# STM32L041xx register map
File version: 1.0
Registers are 32-bit, read-write, reset 0x0 unless marked. A register's access mark holds for its fields unless they carry their own. Offsets are from the block's base; [hi:lo] are bit positions; {n}, {i} and the like mark numbered series; 'fields as' and 'values as' point back to an identical list.

## SPI1 — Serial Peripheral Interface
Base 0x40013000
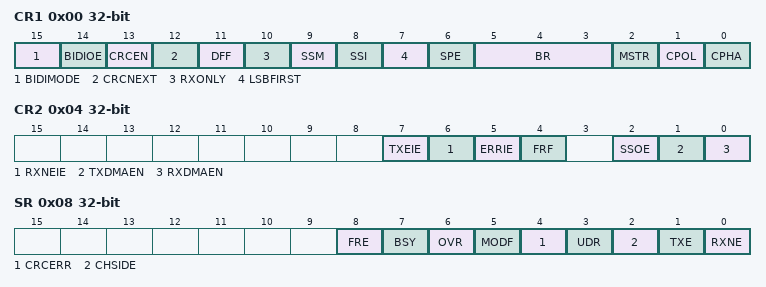
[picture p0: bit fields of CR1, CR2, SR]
0x00 CR1 — SPI Control register 1
  [15] BIDIMODE — Bidirectional data mode enable
  [14] BIDIOE — Output enable in bidirectional mode
  [13] CRCEN — Hardware CRC calculation enable
  [12] CRCNEXT — Transmit CRC next
  [11] DFF — Data Frame Format
    0=DATAWIDTH_8BIT (Data length for SPI transfer: 8 bits); 1=DATAWIDTH_16BIT (Data length for SPI transfer: 16 bits)
  [10] RXONLY — Receive only
  [9] SSM — Software slave management
  [8] SSI — Internal slave select
  [7] LSBFIRST — Frame Format
    1=LSB_FIRST (Data is transmitted/received with the LSB first); 0=MSB_FIRST (Data is transmitted/received with the MSB first)
  [6] SPE — SPI Enable
  [5:3] BR — BR[2:0] bits (Baud Rate Control)
    0=DIV2 (BaudRate control equal to fPCLK/2); 1=DIV4 (BaudRate control equal to fPCLK/4); 2=DIV8 (BaudRate control equal to fPCLK/8); 3=DIV16 (BaudRate control equal to fPCLK/16); 4=DIV32 (BaudRate control equal to fPCLK/32); 5=DIV64 (BaudRate control equal to fPCLK/64); 6=DIV128 (BaudRate control equal to fPCLK/128); 7=DIV256 (BaudRate control equal to fPCLK/256)
  [2] MSTR — Master Selection
  [1] CPOL — Clock Polarity
    0=LOW (Clock to 0 when idle); 1=HIGH (Clock to 1 when idle)
  [0] CPHA — Clock Phase
    0=PHASE_1EDGE (First clock transition is the first data capture edge); 1=PHASE_2EDGE (Second clock transition is the first data capture edge)
0x04 CR2 — SPI Control register 2
  [7] TXEIE — Tx buffer Empty Interrupt Enable
  [6] RXNEIE — RX buffer Not Empty Interrupt Enable
  [5] ERRIE — Error Interrupt Enable
  [4] FRF — Frame Format Enable
    0=MOTOROLA (Motorola mode. Used as default value); 1=TI (TI mode)
  [2] SSOE — SS Output Enable
  [1] TXDMAEN — Tx Buffer DMA Enable
  [0] RXDMAEN — Rx Buffer DMA Enable
0x08 SR — SPI Status register
  [8] FRE — TI frame format error
  [7] BSY — Busy flag
  [6] OVR — Overrun flag
  [5] MODF — Mode fault
  [4] CRCERR — CRC Error flag
  [3] UDR — Underrun flag
  [2] CHSIDE — Channel side
  [1] TXE — Transmit buffer Empty
  [0] RXNE — Receive buffer Not Empty
0x0C DR — SPI data register
  [15:0] DR — Data Register
0x10 CRCPR — SPI CRC polynomial register
  [15:0] CRCPOLY — CRC polynomial register
0x14 RXCRCR — SPI Rx CRC register
  [15:0] RXCRC
0x18 TXCRCR — SPI Tx CRC register
  [15:0] TXCRC

## DBGMCU — Debug MCU
Base 0x40015800
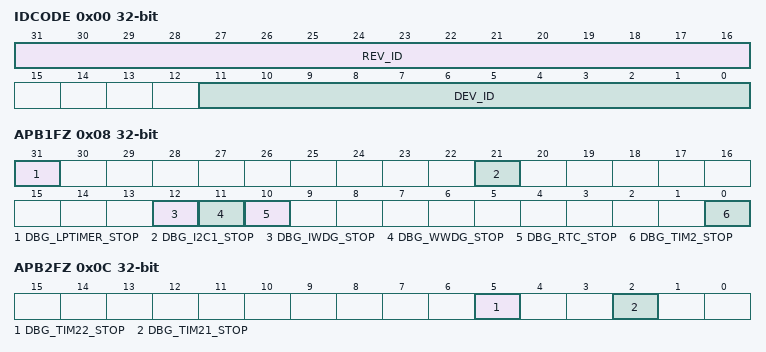
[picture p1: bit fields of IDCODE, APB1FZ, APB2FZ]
0x00 IDCODE — MCU device ID code
  [31:16] REV_ID — REV_ID[15:0] bits (Revision Identifier)
  [11:0] DEV_ID — Device Identifier
0x04 CR — Debug MCU configuration register
  [2:0] DBG — Debug mode mask
0x08 APB1FZ — Debug MCU APB1 freeze register
  [31] DBG_LPTIMER_STOP — LPTIM1 counter stopped when core is halted
  [21] DBG_I2C1_STOP — I2C1 SMBUS timeout mode stopped when Core is halted
  [12] DBG_IWDG_STOP — Debug Independent Watchdog stopped when Core is halted
  [11] DBG_WWDG_STOP — Debug Window Watchdog stopped when Core is halted
  [10] DBG_RTC_STOP — RTC Calendar frozen when core is halted
  [0] DBG_TIM2_STOP — TIM2 counter stopped when core is halted
0x0C APB2FZ — Debug MCU APB2 freeze register
  [5] DBG_TIM22_STOP — TIM22 counter stopped when core is halted
  [2] DBG_TIM21_STOP — TIM21 counter stopped when core is halted

## DMA1
Base 0x40020000
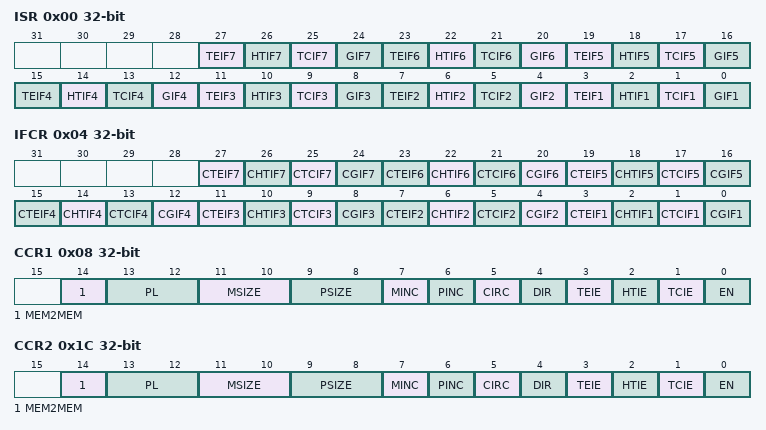
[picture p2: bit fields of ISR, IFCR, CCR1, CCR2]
0x00 ISR — DMA interrupt status register
  [4n-1] TEIF{n} (n=1..7) — Channel {n} Transfer Error flag
  [4n-2] HTIF{n} (n=1..7) — Channel {n} Half Transfer flag
  [4n-3] TCIF{n} (n=1..7) — Channel {n} Transfer Complete flag
  [4n-4] GIF{n} (n=1..7) — Channel {n} Global interrupt flag
0x04 IFCR — DMA interrupt flag clear register
  [4n-1] CTEIF{n} (n=1..7) — Channel {n} Transfer Error clear
  [4n-2] CHTIF{n} (n=1..7) — Channel {n} Half Transfer clear
  [4n-3] CTCIF{n} (n=1..7) — Channel {n} Transfer Complete clear
  [4n-4] CGIF{n} (n=1..7) — Channel {n} Global interrupt clear
0x08 CCR1 — DMA channel x configuration register
  [14] MEM2MEM — Memory to memory mode
  [13:12] PL — PL[1:0] bits(Channel Priority level)
  [11:10] MSIZE — MSIZE[1:0] bits (Memory size)
  [9:8] PSIZE — PSIZE[1:0] bits (Peripheral size)
  [7] MINC — Memory increment mode
  [6] PINC — Peripheral increment mode
  [5] CIRC — Circular mode
  [4] DIR — Data transfer direction
  [3] TEIE — Transfer error interrupt enable
  [2] HTIE — Half Transfer interrupt enable
  [1] TCIE — Transfer complete interrupt enable
  [0] EN — Channel enable
0x0C CNDTR1 — DMA channel x number of data register
  [15:0] NDT — Number of data to Transfer
0x10 CPAR1 — DMA channel x peripheral address register
  [31:0] PA — Peripheral Address
{0x0+0x14*i} CMAR{i} (i=1..7) — DMA channel x memory address register
  [31:0] MA — Memory Address
0x1C CCR2 — DMA channel x configuration register
  fields as CCR1
0x20 CNDTR2 — DMA channel x number of data register
  [15:0] NDT — Number of data to Transfer
0x24 CPAR2 — DMA channel x peripheral address register
  [31:0] PA — Peripheral Address
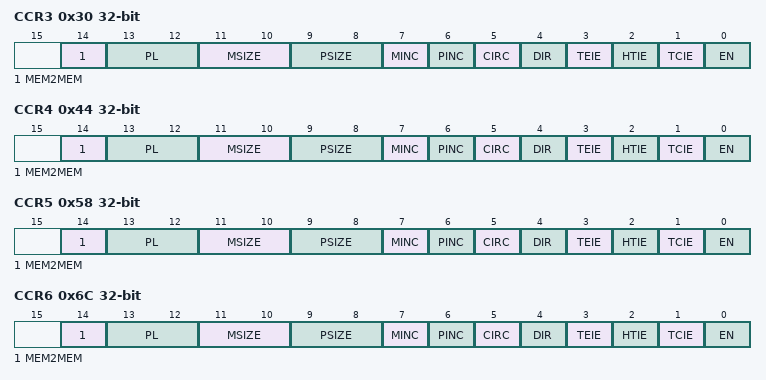
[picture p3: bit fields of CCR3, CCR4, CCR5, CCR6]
0x30 CCR3 — DMA channel x configuration register
  fields as CCR1
0x34 CNDTR3 — DMA channel x number of data register
  [15:0] NDT — Number of data to Transfer
0x38 CPAR3 — DMA channel x peripheral address register
  [31:0] PA — Peripheral Address
0x44 CCR4 — DMA channel x configuration register
  fields as CCR1
0x48 CNDTR4 — DMA channel x number of data register
  [15:0] NDT — Number of data to Transfer
0x4C CPAR4 — DMA channel x peripheral address register
  [31:0] PA — Peripheral Address
0x58 CCR5 — DMA channel x configuration register
  fields as CCR1
0x5C CNDTR5 — DMA channel x number of data register
  [15:0] NDT — Number of data to Transfer
0x60 CPAR5 — DMA channel x peripheral address register
  [31:0] PA — Peripheral Address
0x6C CCR6 — DMA channel x configuration register
  fields as CCR1
0x70 CNDTR6 — DMA channel x number of data register
  [15:0] NDT — Number of data to Transfer
0x74 CPAR6 — DMA channel x peripheral address register
  [31:0] PA — Peripheral Address
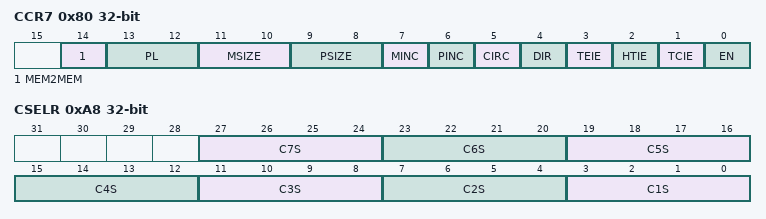
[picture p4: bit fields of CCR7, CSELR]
0x80 CCR7 — DMA channel x configuration register
  fields as CCR1
0x84 CNDTR7 — DMA channel x number of data register
  [15:0] NDT — Number of data to Transfer
0x88 CPAR7 — DMA channel x peripheral address register
  [31:0] PA — Peripheral Address
0xA8 CSELR — DMA channel selection register
  [4n-1:4n-4] C{n}S (n=1..7) — Channel {n} Selection
